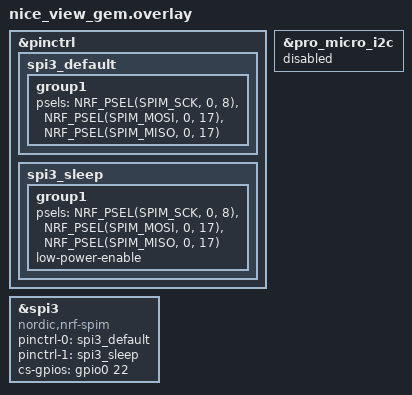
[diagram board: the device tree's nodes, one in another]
/*
 * Copyright (c) 2022 The ZMK Contributors
 *
 * SPDX-License-Identifier: MIT
 */

&pinctrl {
    spi3_default: spi3_default {
        group1 {
            psels = <NRF_PSEL(SPIM_SCK, 0, 8)>,
                <NRF_PSEL(SPIM_MOSI, 0, 17)>,
                <NRF_PSEL(SPIM_MISO, 0, 17)>;
        };
    };
    spi3_sleep: spi3_sleep {
        group1 {
            psels = <NRF_PSEL(SPIM_SCK, 0, 8)>,
                <NRF_PSEL(SPIM_MOSI, 0, 17)>,
                <NRF_PSEL(SPIM_MISO, 0, 17)>;
            low-power-enable;
        };
    };
};

&nice_view_spi: &spi3 {
    compatible = "nordic,nrf-spim";
    pinctrl-0 = <&spi3_default>;
    pinctrl-1 = <&spi3_sleep>;
    pinctrl-names = "default", "sleep";
    cs-gpios = <&gpio0 22 GPIO_ACTIVE_HIGH>; //HAND
};

&pro_micro_i2c {
    status = "disabled";
};
